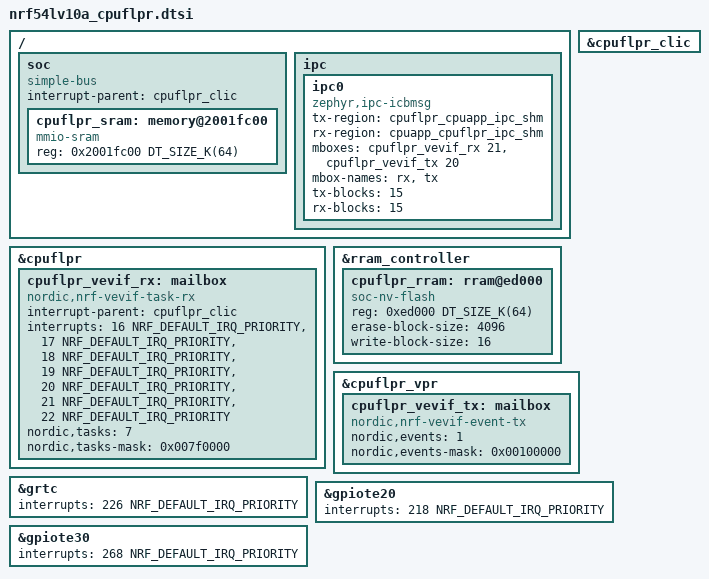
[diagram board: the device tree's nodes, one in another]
/*
 * Copyright (c) 2025 Nordic Semiconductor ASA
 *
 * SPDX-License-Identifier: Apache-2.0
 */

#include <nordic/nrf54lv10a.dtsi>

cpu: &cpuflpr {};

clic: &cpuflpr_clic {};

/delete-node/ &cpuapp;
/delete-node/ &cpuapp_rram;
/delete-node/ &cpuapp_ppb;
/delete-node/ &cpuapp_sram;

/* 123 (APP RAM) + 4 (IPC memory) + 64 (FLPR RAM) + 1 (FLPR hibernation) = 192KB */
/ {
	soc {
		compatible = "simple-bus";
		interrupt-parent = <&cpuflpr_clic>;
		ranges;

		cpuflpr_sram: memory@2001fc00 {
			reg = <0x2001fc00 DT_SIZE_K(64)>;
			ranges = <0x0 0x2001fc00 DT_SIZE_K(64)>;
			compatible = "mmio-sram";
			#address-cells = <1>;
			#size-cells = <1>;
		};
	};

	ipc {
		ipc0: ipc0 {
			compatible = "zephyr,ipc-icbmsg";
			tx-region = <&cpuflpr_cpuapp_ipc_shm>;
			rx-region = <&cpuapp_cpuflpr_ipc_shm>;
			mboxes = <&cpuflpr_vevif_rx 21>, <&cpuflpr_vevif_tx 20>;
			mbox-names = "rx", "tx";
			tx-blocks = <15>;
			rx-blocks = <15>;
			status = "okay";
		};
	};
};

&cpuflpr {
	cpuflpr_vevif_rx: mailbox {
		compatible = "nordic,nrf-vevif-task-rx";
		status = "okay";
		interrupt-parent = <&cpuflpr_clic>;
		interrupts = <16 NRF_DEFAULT_IRQ_PRIORITY>,
			     <17 NRF_DEFAULT_IRQ_PRIORITY>,
			     <18 NRF_DEFAULT_IRQ_PRIORITY>,
			     <19 NRF_DEFAULT_IRQ_PRIORITY>,
			     <20 NRF_DEFAULT_IRQ_PRIORITY>,
			     <21 NRF_DEFAULT_IRQ_PRIORITY>,
			     <22 NRF_DEFAULT_IRQ_PRIORITY>;
		#mbox-cells = <1>;
		nordic,tasks = <7>;
		nordic,tasks-mask = <0x007f0000>;
	};
};

&rram_controller {
	cpuflpr_rram: rram@ed000 {
		reg = <0xed000 DT_SIZE_K(64)>;
		ranges = <0x0 0xed000 DT_SIZE_K(64)>;
		compatible = "soc-nv-flash";
		erase-block-size = <4096>;
		write-block-size = <16>;
		#address-cells = <1>;
		#size-cells = <1>;
	};
};

&cpuflpr_vpr {
	cpuflpr_vevif_tx: mailbox {
		compatible = "nordic,nrf-vevif-event-tx";
		#mbox-cells = <1>;
		nordic,events = <1>;
		nordic,events-mask = <0x00100000>;
		status = "okay";
	};
};

&cpuflpr_clic {
	status = "okay";
};

&grtc {
	interrupts = <226 NRF_DEFAULT_IRQ_PRIORITY>;
};

&gpiote20 {
	interrupts = <218 NRF_DEFAULT_IRQ_PRIORITY>;
};

&gpiote30 {
	interrupts = <268 NRF_DEFAULT_IRQ_PRIORITY>;
};
